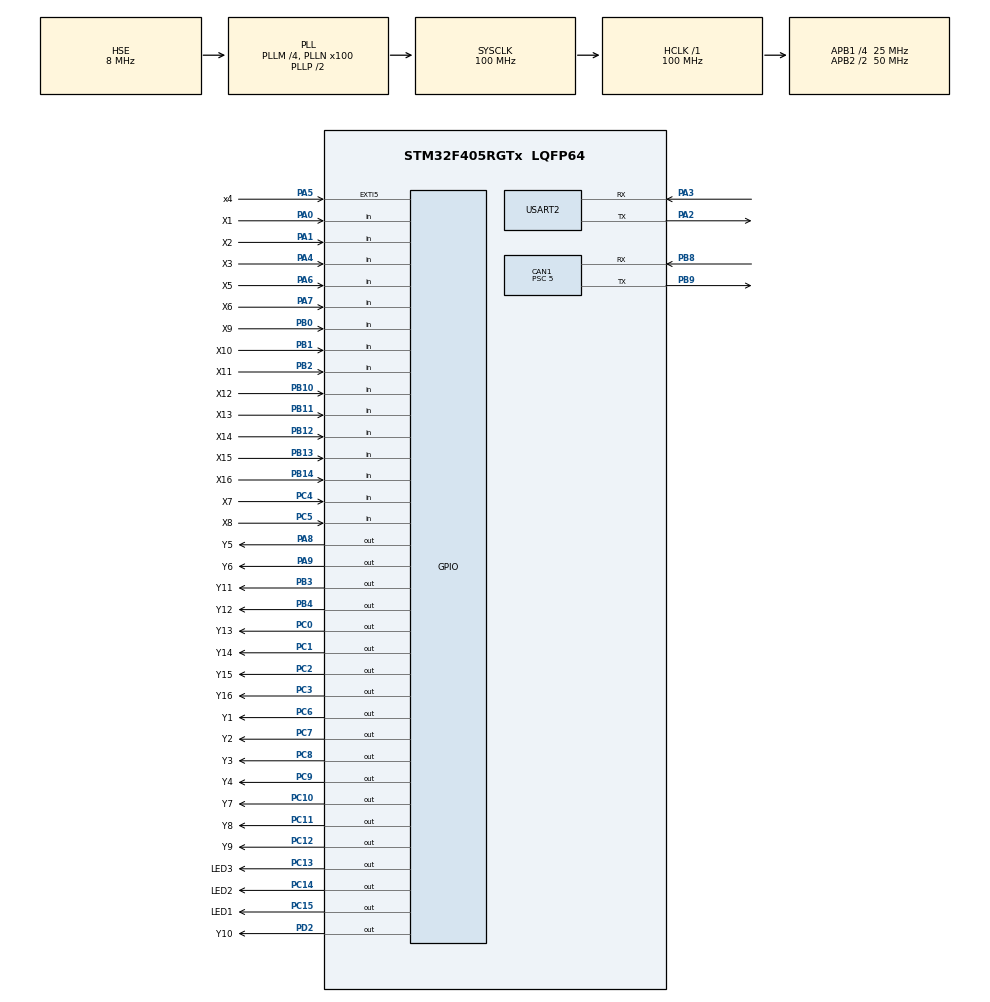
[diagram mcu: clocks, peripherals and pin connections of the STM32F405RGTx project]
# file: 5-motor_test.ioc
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CAN1.ABOM=ENABLE
CAN1.AWUM=ENABLE
CAN1.BS1=CAN_BS1_2TQ
CAN1.BS2=CAN_BS2_2TQ
CAN1.CalculateBaudRate=1000000
CAN1.CalculateTimeBit=1000
CAN1.CalculateTimeQuantum=200.0
CAN1.Prescaler=5
Mcu.Family=STM32F4
Mcu.Name=STM32F405RGTx
Mcu.Package=LQFP64
NVIC.CAN1_RX0_IRQn=true\:1\:0\:true\:false\:true\:true\:true\:true
NVIC.EXTI9_5_IRQn=true\:0\:0\:true\:false\:true\:true\:true\:true
NVIC.PriorityGroup=NVIC_PRIORITYGROUP_4
NVIC.TIM3_IRQn=true\:1\:0\:true\:false\:true\:true\:true\:true
NVIC.TIM6_DAC_IRQn=true\:1\:0\:true\:false\:true\:true\:true\:true
NVIC.USART2_IRQn=true\:2\:0\:true\:false\:true\:true\:true\:true
PA0-WKUP.GPIO_Label=X1
PA0-WKUP.Signal=GPIO_Input
PA1.GPIO_Label=X2
PA1.Signal=GPIO_Input
PA11.Signal=USB_OTG_FS_DM
PA12.Signal=USB_OTG_FS_DP
PA13.Mode=Serial_Wire
PA13.Signal=SYS_JTMS-SWDIO
PA14.Mode=Serial_Wire
PA14.Signal=SYS_JTCK-SWCLK
PA2.Mode=Asynchronous
PA2.Signal=USART2_TX
PA3.Mode=Asynchronous
PA3.Signal=USART2_RX
PA4.GPIO_Label=X3
PA4.Signal=GPIO_Input
PA5.GPIO_Label=x4
PA5.GPIO_ModeDefaultEXTI=GPIO_MODE_IT_RISING_FALLING
PA5.Signal=GPXTI5
PA6.GPIO_Label=X5
PA6.Signal=GPIO_Input
PA7.GPIO_Label=X6
PA7.Signal=GPIO_Input
PA8.GPIO_Label=Y5
PA8.PinState=GPIO_PIN_SET
PA8.Signal=GPIO_Output
PA9.GPIO_Label=Y6
PA9.PinState=GPIO_PIN_SET
PA9.Signal=GPIO_Output
PB0.GPIO_Label=X9
PB0.Signal=GPIO_Input
PB1.GPIO_Label=X10
PB1.Signal=GPIO_Input
PB10.GPIO_Label=X12
PB10.Signal=GPIO_Input
PB11.GPIO_Label=X13
PB11.Signal=GPIO_Input
PB12.GPIO_Label=X14
PB12.Signal=GPIO_Input
PB13.GPIO_Label=X15
PB13.Signal=GPIO_Input
PB14.GPIO_Label=X16
PB14.Signal=GPIO_Input
PB2.GPIO_Label=X11
PB2.Signal=GPIO_Input
PB3.GPIO_Label=Y11
PB3.PinState=GPIO_PIN_SET
PB3.Signal=GPIO_Output
PB4.GPIO_Label=Y12
PB4.PinState=GPIO_PIN_SET
PB4.Signal=GPIO_Output
PB6.Signal=USART1_TX
PB7.Signal=USART1_RX
PB8.Mode=CAN_Activate
PB8.Signal=CAN1_RX
PB9.Mode=CAN_Activate
PB9.Signal=CAN1_TX
PC0.GPIO_Label=Y13
PC0.PinState=GPIO_PIN_SET
PC0.Signal=GPIO_Output
PC1.GPIO_Label=Y14
PC1.PinState=GPIO_PIN_SET
PC1.Signal=GPIO_Output
PC10.GPIO_Label=Y7
PC10.PinState=GPIO_PIN_SET
PC10.Signal=GPIO_Output
PC11.GPIO_Label=Y8
PC11.PinState=GPIO_PIN_SET
PC11.Signal=GPIO_Output
PC12.GPIO_Label=Y9
PC12.PinState=GPIO_PIN_SET
PC12.Signal=GPIO_Output
PC13-ANTI_TAMP.GPIO_Label=LED3
PC13-ANTI_TAMP.PinState=GPIO_PIN_SET
PC13-ANTI_TAMP.Signal=GPIO_Output
PC14-OSC32_IN.GPIO_Label=LED2
PC14-OSC32_IN.PinState=GPIO_PIN_SET
PC14-OSC32_IN.Signal=GPIO_Output
PC15-OSC32_OUT.GPIO_Label=LED1
PC15-OSC32_OUT.PinState=GPIO_PIN_SET
PC15-OSC32_OUT.Signal=GPIO_Output
PC2.GPIO_Label=Y15
PC2.PinState=GPIO_PIN_SET
PC2.Signal=GPIO_Output
PC3.GPIO_Label=Y16
PC3.PinState=GPIO_PIN_SET
PC3.Signal=GPIO_Output
PC4.GPIO_Label=X7
PC4.Signal=GPIO_Input
PC5.GPIO_Label=X8
PC5.Signal=GPIO_Input
PC6.GPIO_Label=Y1
PC6.PinState=GPIO_PIN_SET
PC6.Signal=GPIO_Output
PC7.GPIO_Label=Y2
PC7.PinState=GPIO_PIN_SET
PC7.Signal=GPIO_Output
PC8.GPIO_Label=Y3
PC8.PinState=GPIO_PIN_SET
PC8.Signal=GPIO_Output
PC9.GPIO_Label=Y4
PC9.PinState=GPIO_PIN_SET
PC9.Signal=GPIO_Output
PD2.GPIO_Label=Y10
PD2.PinState=GPIO_PIN_SET
PD2.Signal=GPIO_Output
PH0-OSC_IN.Mode=HSE-External-Oscillator
PH0-OSC_IN.Signal=RCC_OSC_IN
PH1-OSC_OUT.Mode=HSE-External-Oscillator
PH1-OSC_OUT.Signal=RCC_OSC_OUT
ProjectManager.HeapSize=0x200
ProjectManager.StackSize=0x400
ProjectManager.TargetToolchain=MDK-ARM V5.32
RCC.48MHZClocksFreq_Value=50000000
RCC.AHBFreq_Value=100000000
RCC.APB1CLKDivider=RCC_HCLK_DIV4
RCC.APB1Freq_Value=25000000
RCC.APB1TimFreq_Value=50000000
RCC.APB2CLKDivider=RCC_HCLK_DIV2
RCC.APB2Freq_Value=50000000
RCC.APB2TimFreq_Value=100000000
RCC.CortexFreq_Value=100000000
RCC.HCLKFreq_Value=100000000
RCC.HSE_VALUE=8000000
RCC.HSI_VALUE=16000000
RCC.LSE_VALUE=32768
RCC.PLLM=4
RCC.PLLN=100
RCC.PLLSourceVirtual=RCC_PLLSOURCE_HSE
RCC.SYSCLKFreq_VALUE=100000000
RCC.SYSCLKSource=RCC_SYSCLKSOURCE_PLLCLK
RCC.VCOOutputFreq_Value=200000000
TIM3.Period=4999
TIM3.Prescaler=4999
TIM6.Period=4999
TIM6.Prescaler=4999
USART2.VirtualMode=VM_ASYNC
VP_TIM3_VS_ClockSourceINT.Mode=Internal
VP_TIM6_VS_ClockSourceINT.Mode=Enable_Timer
board=custom

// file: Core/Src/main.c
/* USER CODE BEGIN Header */
/* USER CODE END Header */
#include "main.h"
#include "can.h"
#include "tim.h"
#include "usart.h"
#include "gpio.h"

/* USER CODE BEGIN Includes */
#include "motor.h"
/* USER CODE END Includes */

void SystemClock_Config(void);

int main(void)
{

  /* MCU Configuration--------------------------------------------------------*/

  /* Reset of all peripherals, Initializes the Flash interface and the Systick. */
  HAL_Init();

  /* Configure the system clock */
  SystemClock_Config();

  /* Initialize all configured peripherals */
  MX_GPIO_Init();
  MX_TIM3_Init();
  MX_TIM6_Init();
  MX_CAN1_Init();
  MX_USART2_UART_Init();
  /* USER CODE BEGIN 2 */
  HAL_UART_Receive_IT(&huart2, RxBuff, 1);
  CAN1_Config();
  Motor_Init();
  Position_Init(8,8,10);
  /* USER CODE END 2 */

  /* Infinite loop */
  /* USER CODE BEGIN WHILE */
  HAL_GPIO_WritePin(Y6_GPIO_Port, Y6_Pin, GPIO_PIN_RESET);//yellowled_S
  HAL_Delay(1000);
  motor_AllGoHome();
  HAL_Delay(1000);

  while (1)
  {
    /* USER CODE END WHILE */

    /* USER CODE BEGIN 3 */

	Sys_Run(tray_num-1);
	HAL_Delay(50);
	// HAL_GPIO_TogglePin(LED3_GPIO_Port, LED3_Pin);
  }
  /* USER CODE END 3 */
}

void SystemClock_Config(void)
{
  RCC_OscInitTypeDef RCC_OscInitStruct = {0};
  RCC_ClkInitTypeDef RCC_ClkInitStruct = {0};

  /** Configure the main internal regulator output voltage
  */
  __HAL_RCC_PWR_CLK_ENABLE();
  __HAL_PWR_VOLTAGESCALING_CONFIG(PWR_REGULATOR_VOLTAGE_SCALE1);

  /** Initializes the RCC Oscillators according to the specified parameters
  * in the RCC_OscInitTypeDef structure.
  */
  RCC_OscInitStruct.OscillatorType = RCC_OSCILLATORTYPE_HSE;
  RCC_OscInitStruct.HSEState = RCC_HSE_ON;
  RCC_OscInitStruct.PLL.PLLState = RCC_PLL_ON;
  RCC_OscInitStruct.PLL.PLLSource = RCC_PLLSOURCE_HSE;
  RCC_OscInitStruct.PLL.PLLM = 4;
  RCC_OscInitStruct.PLL.PLLN = 100;
  RCC_OscInitStruct.PLL.PLLP = RCC_PLLP_DIV2;
  RCC_OscInitStruct.PLL.PLLQ = 4;
  if (HAL_RCC_OscConfig(&RCC_OscInitStruct) != HAL_OK)
  {
    Error_Handler();
  }

  /** Initializes the CPU, AHB and APB buses clocks
  */
  RCC_ClkInitStruct.ClockType = RCC_CLOCKTYPE_HCLK|RCC_CLOCKTYPE_SYSCLK
                              |RCC_CLOCKTYPE_PCLK1|RCC_CLOCKTYPE_PCLK2;
  RCC_ClkInitStruct.SYSCLKSource = RCC_SYSCLKSOURCE_PLLCLK;
  RCC_ClkInitStruct.AHBCLKDivider = RCC_SYSCLK_DIV1;
  RCC_ClkInitStruct.APB1CLKDivider = RCC_HCLK_DIV4;
  RCC_ClkInitStruct.APB2CLKDivider = RCC_HCLK_DIV2;

  if (HAL_RCC_ClockConfig(&RCC_ClkInitStruct, FLASH_LATENCY_3) != HAL_OK)
  {
    Error_Handler();
  }
}

void Error_Handler(void)
{
  __disable_irq();
  while (1)
  {
  }
}
